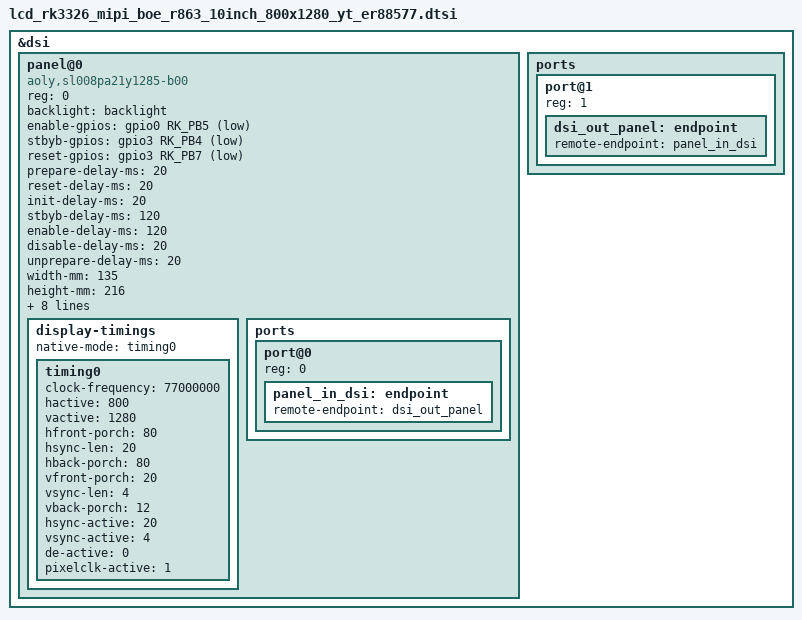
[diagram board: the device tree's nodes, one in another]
/*
* incar mipi lcd
*/
&dsi {
	status = "okay";

	panel@0 {
		compatible = "aoly,sl008pa21y1285-b00", "simple-panel-dsi";
		reg = <0>;
		backlight = <&backlight>;
		enable-gpios = <&gpio0 RK_PB5 GPIO_ACTIVE_LOW>;
		stbyb-gpios = <&gpio3 RK_PB4 GPIO_ACTIVE_LOW>;
		
		reset-gpios = <&gpio3 RK_PB7 GPIO_ACTIVE_LOW>;
		prepare-delay-ms = <20>;
		reset-delay-ms = <20>;
		init-delay-ms = <20>;
		stbyb-delay-ms = <120>;
		enable-delay-ms = <120>;
		disable-delay-ms = <20>;
		unprepare-delay-ms = <20>;

		width-mm = <135>;
		height-mm = <216>;

		dsi,flags = <(MIPI_DSI_MODE_VIDEO | MIPI_DSI_MODE_VIDEO_BURST |
			      MIPI_DSI_MODE_LPM | MIPI_DSI_MODE_EOT_PACKET)>;
		dsi,format = <MIPI_DSI_FMT_RGB888>;
		dsi,lanes = <4>;

		panel-init-sequence = [
		
		39 00 03 E0 AB BA 
		39 00 03 E1 BA AB 
		39 00 05 B1 10 01 47 FF 
		39 00 07 B2 0c 14 04 50 50 14 
		39 00 04 B3 56 53 00 
		39 00 04 B4 33 30 04 
		39 00 08 B6 B0 00 00 10 00 10 00 
		39 00 08 B8 05 12 29 49 48 00 00 
		39 00 27 B9 7C 65 55 49 46 36 3B 24 3D 3C 3D 5C 4C 55 47 46 39 26 06 7C 65 55 49 46 36 3B 24 3D 3C 3D 5C 4C 55 47 46 39 26 06 
		39 00 11 C0 FF 87 12 34 44 44 44 44 98 04 98 04 0F 00 00 C1 
		39 00 0B C1 54 94 02 85 9F 00 7F 00 54 00 
		39 00 0D C2 17 09 08 89 08 11 22 20 44 FF 18 00 
		39 00 17 C3 86 46 05 05 1C 1C 1D 1D 02 1F 1F 1E 1E 0F 0F 0D 0D 13 13 11 11 00 
		39 00 17 C4 07 07 04 04 1C 1C 1D 1D 02 1F 1F 1E 1E 0E 0E 0C 0C 12 12 10 10 00 
		39 00 03 C6 21 21 
		39 00 07 C8 21 00 31 42 34 16 
		39 00 03 CA CB 43 
		39 00 09 CD 0E 4B 4B 20 19 6B 06 B3 
		39 00 05 D2 E3 2B 38 00 
		39 00 0C D4 00 01 00 0E 04 44 08 10 00 00 00 
		39 00 09 E6 00 01 FF FF FF FF FF FF 
		39 00 06 F0 12 03 20 00 FF 
		15 00 02 F3 00 
		05 78 01 11 
		05 14 01 29 
		
		
		];

		panel-exit-sequence = [
			05 14 01 28
			05 78 01 10
		];

			
		display-timings {
			native-mode = <&timing0>;

			timing0: timing0 {
				clock-frequency = <77000000>;
				hactive = <800>;
				vactive = <1280>;
				hfront-porch = <80>;
				hsync-len = <20>;
				hback-porch = <80>;
				vfront-porch = <20>;
				vsync-len = <4>;
				vback-porch = <12>;
				hsync-active = <20>;
				vsync-active = <4>;
				de-active = <0>;
				pixelclk-active = <1>;
			};
		};
		ports {
			#address-cells = <1>;
			#size-cells = <0>;

			port@0 {
				reg = <0>;
				panel_in_dsi: endpoint {
					remote-endpoint = <&dsi_out_panel>;
				};
			};
		};
	};

	ports {
		#address-cells = <1>;
		#size-cells = <0>;

		port@1 {
			reg = <1>;
			dsi_out_panel: endpoint {
				remote-endpoint = <&panel_in_dsi>;
			};
		};
	};
};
